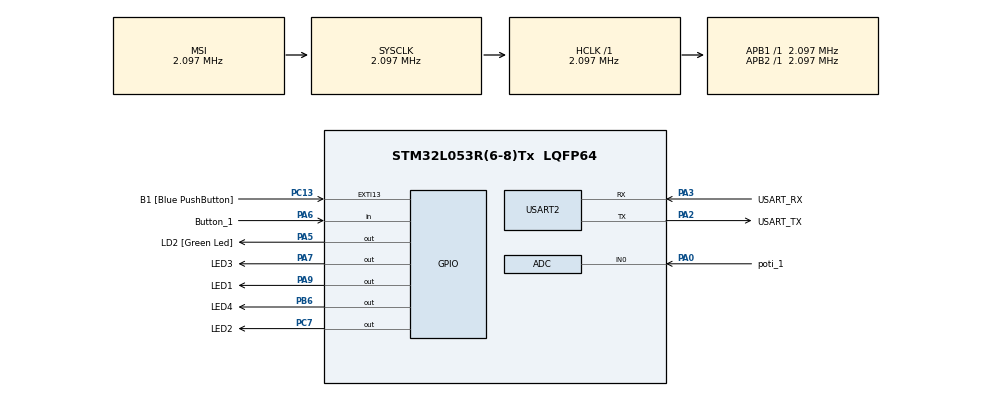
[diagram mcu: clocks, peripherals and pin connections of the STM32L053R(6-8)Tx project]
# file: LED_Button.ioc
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Mcu.Family=STM32L0
Mcu.Name=STM32L053R(6-8)Tx
Mcu.Package=LQFP64
PA0.GPIO_Label=poti_1
PA0.Mode=IN0
PA0.Signal=ADC_IN0
PA13.GPIO_Label=TMS
PA13.Signal=SYS_SWDIO
PA14.GPIO_Label=TCK
PA14.Signal=SYS_SWCLK
PA2.GPIO_Label=USART_TX
PA2.Mode=Asynchronous
PA2.Signal=USART2_TX
PA3.GPIO_Label=USART_RX
PA3.Mode=Asynchronous
PA3.Signal=USART2_RX
PA5.GPIO_Label=LD2 [Green Led]
PA5.PinState=GPIO_PIN_SET
PA5.Signal=GPIO_Output
PA6.GPIO_Label=Button_1
PA6.GPIO_PuPd=GPIO_PULLUP
PA6.Signal=GPIO_Input
PA7.GPIO_Label=LED3
PA7.PinState=GPIO_PIN_SET
PA7.Signal=GPIO_Output
PA9.GPIO_Label=LED1
PA9.PinState=GPIO_PIN_SET
PA9.Signal=GPIO_Output
PB6.GPIO_Label=LED4
PB6.PinState=GPIO_PIN_SET
PB6.Signal=GPIO_Output
PC13.GPIO_Label=B1 [Blue PushButton]
PC13.GPIO_ModeDefaultEXTI=GPIO_MODE_IT_FALLING
PC13.Signal=GPXTI13
PC14-OSC32_IN.Signal=RCC_OSC32_IN
PC15-OSC32_OUT.Signal=RCC_OSC32_OUT
PC7.GPIO_Label=LED2
PC7.GPIO_Speed=GPIO_SPEED_FREQ_LOW
PC7.PinState=GPIO_PIN_SET
PC7.Signal=GPIO_Output
PH0-OSC_IN.Signal=RCC_OSC_IN
PH1-OSC_OUT.Signal=RCC_OSC_OUT
ProjectManager.HeapSize=0x200
ProjectManager.StackSize=0x400
ProjectManager.TargetToolchain=TrueSTUDIO
RCC.AHBFreq_Value=2097000
RCC.APB1Freq_Value=2097000
RCC.APB1TimFreq_Value=2097000
RCC.APB2Freq_Value=2097000
RCC.APB2TimFreq_Value=2097000
RCC.HSE_VALUE=8000000
RCC.HSI16_VALUE=16000000
RCC.HSI48_VALUE=48000000
RCC.HSI_VALUE=16000000
RCC.LSEState=RCC_LSE_ON
RCC.LSE_VALUE=32768
RCC.MSI_VALUE=2097000
RCC.SYSCLKFreq_VALUE=2097000
RCC.VCOOutputFreq_Value=48000000
USART2.VirtualMode-Asynchronous=VM_ASYNC
VP_IWDG_VS_IWDG.Mode=IWDG_Activate
board=NUCLEO-L053R8

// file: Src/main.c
/* USER CODE BEGIN Header */
/**
  ******************************************************************************
  * @file           : main.c
  * @brief          : Main program body
  ******************************************************************************
  * @attention
  *
  * <h2><center>&copy; Copyright (c) 2019 STMicroelectronics.
  * All rights reserved.</center></h2>
  *
  * This software component is licensed by ST under BSD 3-Clause license,
  * the "License"; You may not use this file except in compliance with the
  * License. You may obtain a copy of the License at:
  *                        opensource.org/licenses/BSD-3-Clause
  *
  ******************************************************************************
  */
/* USER CODE END Header */

#include "main.h"

/* USER CODE BEGIN Includes */

#include <stdio.h>

/* USER CODE END Includes */

ADC_HandleTypeDef hadc;

UART_HandleTypeDef huart2;

void SystemClock_Config(void);
static void MX_GPIO_Init(void);
static void MX_USART2_UART_Init(void);
static void MX_ADC_Init(void);

int main(void)
{

  /* MCU Configuration--------------------------------------------------------*/

  /* Reset of all peripherals, Initializes the Flash interface and the Systick. */
  HAL_Init();

  /* Configure the system clock */
  SystemClock_Config();

  /* Initialize all configured peripherals */
  MX_GPIO_Init();
  MX_USART2_UART_Init();
  MX_ADC_Init();

  /* Infinite loop */
  while (1)
  {

    /* USER CODE BEGIN 3 */

	 	  HAL_GPIO_WritePin(LED1_GPIO_Port, LED1_Pin, GPIO_PIN_SET); //Set Pin high
	 	  HAL_GPIO_WritePin(LED2_GPIO_Port, LED2_Pin, GPIO_PIN_SET); //Set Pin high
	 	  HAL_GPIO_WritePin(LED3_GPIO_Port, LED3_Pin, GPIO_PIN_SET); //Set Pin high
	 	  HAL_GPIO_WritePin(LED4_GPIO_Port, LED4_Pin, GPIO_PIN_SET); //Set Pin high
	 	  HAL_Delay(500)
		  HAL_GPIO_WritePin(LED1_GPIO_Port, LED1_Pin, GPIO_PIN_RESET); //Set Pin low
		  HAL_GPIO_WritePin(LED2_GPIO_Port, LED2_Pin, GPIO_PIN_RESET); //Set Pin low
		  HAL_GPIO_WritePin(LED3_GPIO_Port, LED3_Pin, GPIO_PIN_RESET); //Set Pin low
		  HAL_GPIO_WritePin(LED4_GPIO_Port, LED4_Pin, GPIO_PIN_RESET); //Set Pin low

  }
  /* USER CODE END 3 */
}

void SystemClock_Config(void)
{
  RCC_OscInitTypeDef RCC_OscInitStruct = {0};
  RCC_ClkInitTypeDef RCC_ClkInitStruct = {0};
  RCC_PeriphCLKInitTypeDef PeriphClkInit = {0};

  /** Configure the main internal regulator output voltage
  */
  __HAL_PWR_VOLTAGESCALING_CONFIG(PWR_REGULATOR_VOLTAGE_SCALE1);
  /** Initializes the CPU, AHB and APB busses clocks
  */
  RCC_OscInitStruct.OscillatorType = RCC_OSCILLATORTYPE_MSI;
  RCC_OscInitStruct.MSIState = RCC_MSI_ON;
  RCC_OscInitStruct.MSICalibrationValue = 0;
  RCC_OscInitStruct.MSIClockRange = RCC_MSIRANGE_5;
  RCC_OscInitStruct.PLL.PLLState = RCC_PLL_NONE;
  if (HAL_RCC_OscConfig(&RCC_OscInitStruct) != HAL_OK)
  {
    Error_Handler();
  }
  /** Initializes the CPU, AHB and APB busses clocks
  */
  RCC_ClkInitStruct.ClockType = RCC_CLOCKTYPE_HCLK|RCC_CLOCKTYPE_SYSCLK
                              |RCC_CLOCKTYPE_PCLK1|RCC_CLOCKTYPE_PCLK2;
  RCC_ClkInitStruct.SYSCLKSource = RCC_SYSCLKSOURCE_MSI;
  RCC_ClkInitStruct.AHBCLKDivider = RCC_SYSCLK_DIV1;
  RCC_ClkInitStruct.APB1CLKDivider = RCC_HCLK_DIV1;
  RCC_ClkInitStruct.APB2CLKDivider = RCC_HCLK_DIV1;

  if (HAL_RCC_ClockConfig(&RCC_ClkInitStruct, FLASH_LATENCY_0) != HAL_OK)
  {
    Error_Handler();
  }
  PeriphClkInit.PeriphClockSelection = RCC_PERIPHCLK_USART2;
  PeriphClkInit.Usart2ClockSelection = RCC_USART2CLKSOURCE_PCLK1;
  if (HAL_RCCEx_PeriphCLKConfig(&PeriphClkInit) != HAL_OK)
  {
    Error_Handler();
  }
}

static void MX_ADC_Init(void)
{

  ADC_ChannelConfTypeDef sConfig = {0};

  /** Configure the global features of the ADC (Clock, Resolution, Data Alignment and number of conversion)
  */
  hadc.Instance = ADC1;
  hadc.Init.OversamplingMode = DISABLE;
  hadc.Init.ClockPrescaler = ADC_CLOCK_SYNC_PCLK_DIV1;
  hadc.Init.Resolution = ADC_RESOLUTION_12B;
  hadc.Init.SamplingTime = ADC_SAMPLETIME_1CYCLE_5;
  hadc.Init.ScanConvMode = ADC_SCAN_DIRECTION_FORWARD;
  hadc.Init.DataAlign = ADC_DATAALIGN_RIGHT;
  hadc.Init.ContinuousConvMode = DISABLE;
  hadc.Init.DiscontinuousConvMode = DISABLE;
  hadc.Init.ExternalTrigConvEdge = ADC_EXTERNALTRIGCONVEDGE_NONE;
  hadc.Init.ExternalTrigConv = ADC_SOFTWARE_START;
  hadc.Init.DMAContinuousRequests = DISABLE;
  hadc.Init.EOCSelection = ADC_EOC_SINGLE_CONV;
  hadc.Init.Overrun = ADC_OVR_DATA_PRESERVED;
  hadc.Init.LowPowerAutoWait = DISABLE;
  hadc.Init.LowPowerFrequencyMode = DISABLE;
  hadc.Init.LowPowerAutoPowerOff = DISABLE;
  if (HAL_ADC_Init(&hadc) != HAL_OK)
  {
    Error_Handler();
  }
  /** Configure for the selected ADC regular channel to be converted.
  */
  sConfig.Channel = ADC_CHANNEL_0;
  sConfig.Rank = ADC_RANK_CHANNEL_NUMBER;
  if (HAL_ADC_ConfigChannel(&hadc, &sConfig) != HAL_OK)
  {
    Error_Handler();
  }

}

static void MX_USART2_UART_Init(void)
{

  huart2.Instance = USART2;
  huart2.Init.BaudRate = 115200;
  huart2.Init.WordLength = UART_WORDLENGTH_8B;
  huart2.Init.StopBits = UART_STOPBITS_1;
  huart2.Init.Parity = UART_PARITY_NONE;
  huart2.Init.Mode = UART_MODE_TX_RX;
  huart2.Init.HwFlowCtl = UART_HWCONTROL_NONE;
  huart2.Init.OverSampling = UART_OVERSAMPLING_16;
  huart2.Init.OneBitSampling = UART_ONE_BIT_SAMPLE_DISABLE;
  huart2.AdvancedInit.AdvFeatureInit = UART_ADVFEATURE_NO_INIT;
  if (HAL_UART_Init(&huart2) != HAL_OK)
  {
    Error_Handler();
  }

}

static void MX_GPIO_Init(void)
{
  GPIO_InitTypeDef GPIO_InitStruct = {0};

  /* GPIO Ports Clock Enable */
  __HAL_RCC_GPIOC_CLK_ENABLE();
  __HAL_RCC_GPIOH_CLK_ENABLE();
  __HAL_RCC_GPIOA_CLK_ENABLE();
  __HAL_RCC_GPIOB_CLK_ENABLE();

  /*Configure GPIO pin Output Level */
  HAL_GPIO_WritePin(GPIOA, LD2_Pin|LED3_Pin|LED1_Pin, GPIO_PIN_SET);

  /*Configure GPIO pin Output Level */
  HAL_GPIO_WritePin(LED2_GPIO_Port, LED2_Pin, GPIO_PIN_SET);

  /*Configure GPIO pin Output Level */
  HAL_GPIO_WritePin(LED4_GPIO_Port, LED4_Pin, GPIO_PIN_SET);

  /*Configure GPIO pin : B1_Pin */
  GPIO_InitStruct.Pin = B1_Pin;
  GPIO_InitStruct.Mode = GPIO_MODE_IT_FALLING;
  GPIO_InitStruct.Pull = GPIO_NOPULL;
  HAL_GPIO_Init(B1_GPIO_Port, &GPIO_InitStruct);

  /*Configure GPIO pins : LD2_Pin LED3_Pin LED1_Pin */
  GPIO_InitStruct.Pin = LD2_Pin|LED3_Pin|LED1_Pin;
  GPIO_InitStruct.Mode = GPIO_MODE_OUTPUT_PP;
  GPIO_InitStruct.Pull = GPIO_NOPULL;
  GPIO_InitStruct.Speed = GPIO_SPEED_FREQ_LOW;
  HAL_GPIO_Init(GPIOA, &GPIO_InitStruct);

  /*Configure GPIO pin : Button_1_Pin */
  GPIO_InitStruct.Pin = Button_1_Pin;
  GPIO_InitStruct.Mode = GPIO_MODE_INPUT;
  GPIO_InitStruct.Pull = GPIO_PULLUP;
  HAL_GPIO_Init(Button_1_GPIO_Port, &GPIO_InitStruct);

  /*Configure GPIO pin : LED2_Pin */
  GPIO_InitStruct.Pin = LED2_Pin;
  GPIO_InitStruct.Mode = GPIO_MODE_OUTPUT_PP;
  GPIO_InitStruct.Pull = GPIO_NOPULL;
  GPIO_InitStruct.Speed = GPIO_SPEED_FREQ_LOW;
  HAL_GPIO_Init(LED2_GPIO_Port, &GPIO_InitStruct);

  /*Configure GPIO pin : LED4_Pin */
  GPIO_InitStruct.Pin = LED4_Pin;
  GPIO_InitStruct.Mode = GPIO_MODE_OUTPUT_PP;
  GPIO_InitStruct.Pull = GPIO_NOPULL;
  GPIO_InitStruct.Speed = GPIO_SPEED_FREQ_LOW;
  HAL_GPIO_Init(LED4_GPIO_Port, &GPIO_InitStruct);

}

void Error_Handler(void)
{
}

/************************ (C) COPYRIGHT STMicroelectronics *****END OF FILE****/
